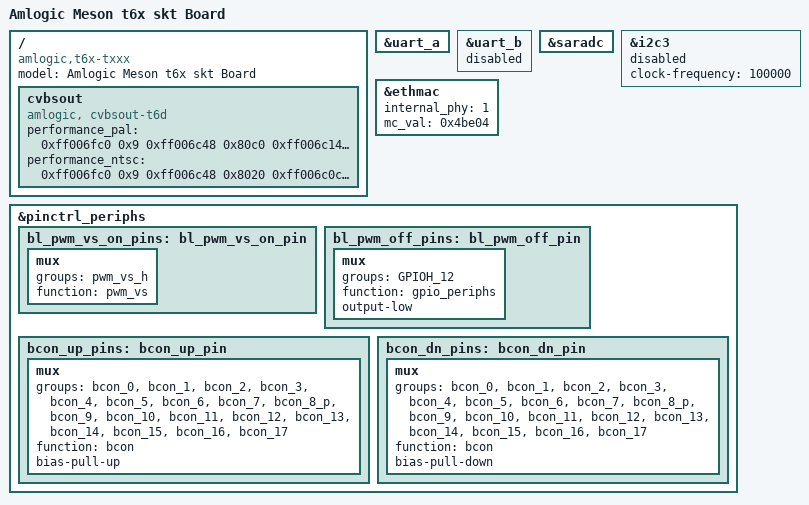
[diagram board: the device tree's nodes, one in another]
// SPDX-License-Identifier: (GPL-2.0+ OR MIT)
/*
 * Copyright (c) 2019 Amlogic, Inc. All rights reserved.
 */

/dts-v1/;

#include "amlogic/meson-t6x-skt.dtsi"
#include "amlogic/meson-t6x-panel.dtsi"

/ {
	compatible =  "amlogic,t6x-txxx", "amlogic,meson-t6x";
	model = "Amlogic Meson t6x skt Board";

	cvbsout {
		compatible = "amlogic, cvbsout-t6d";
		status = "okay";

		/* performance: reg_address, reg_value */
		/* t6d */
		/* pal default Matrx625 CTCC value */
		performance_pal = <0xff006fc0  0x9 /* 0x1bf0 << 2 + 0xff000000 */
			0xff006c48  0x80c0 /* 0x1b12 */
			0xff006c14  0xf7 /* 0x1b05 */
			0xff006d58  0x333 /* 0x1b56 */
			0xff007164  0xf25c /* 0x1c59 */
			0xffff  0x0>; /* ending flag */
		performance_ntsc = <0xff006fc0  0x9 /* 0x1bf0 << 2 + 0xff000000 */
			0xff006c48  0x8020 /* 0x1b12 */
			0xff006c0c  0x0 /* 0x1b03 */
			0xff006c10  0x0 /* 0x1b04 */
			0xff006c14  0x0 /* 0x1b05 */
			0xff006d58  0x333 /* 0x1b56 */
			0xff007164  0xf850 /* 0x1c59 */
			0xffff  0x0>; /* ending flag */
	};
};

/* This UART is brought out to the DB9 connector */
&uart_a {
	status = "okay";
};

&uart_b {
	status = "disabled";
};

&saradc {
	status = "okay";
};

/* demo for i2c user */
&i2c3 {
	status= "disabled";
	clock-frequency = <100000>;
	/* pinctrl-names = "default";*/
	/* pinctrl-0 = <&i2c3_master_pins2>;*/
};

&ethmac {
	status = "okay";
	internal_phy = <1>;
	mc_val = <0x4be04>;
	/*mc_val = <0x1621>;*/
};

&pinctrl_periphs {
	/*backlight*/
	bl_pwm_vs_on_pins:bl_pwm_vs_on_pin {
		mux {
			groups = "pwm_vs_h";
			function = "pwm_vs";
		};
	};
	bl_pwm_off_pins:bl_pwm_off_pin {
		mux {
			groups = "GPIOH_12";
			function = "gpio_periphs";
			output-low;
		};
	};
	bcon_up_pins:bcon_up_pin {
		mux {
			groups = "bcon_0",
				"bcon_1",
				"bcon_2",
				"bcon_3",
				"bcon_4",
				"bcon_5",
				"bcon_6",
				"bcon_7",
				"bcon_8_p",
				"bcon_9",
				"bcon_10",
				"bcon_11",
				"bcon_12",
				"bcon_13",
				"bcon_14",
				"bcon_15",
				"bcon_16",
				"bcon_17";
			function = "bcon";
			bias-pull-up;
		};
	};
	bcon_dn_pins:bcon_dn_pin {
		mux {
			groups = "bcon_0",
				"bcon_1",
				"bcon_2",
				"bcon_3",
				"bcon_4",
				"bcon_5",
				"bcon_6",
				"bcon_7",
				"bcon_8_p",
				"bcon_9",
				"bcon_10",
				"bcon_11",
				"bcon_12",
				"bcon_13",
				"bcon_14",
				"bcon_15",
				"bcon_16",
				"bcon_17";
			function = "bcon";
			bias-pull-down;
		};
	};
}; /* end of pinctrl_periphs */
